# DA1470x register map
Vendor: Dialog; Series: DA1470x; File version: 1.2
CPU: CM33 r0p2, little endian, MPU, FPU, DSP, VTOR, 4 interrupt priority bits
Registers are 32-bit, read-write, reset 0x0 unless marked. A register's access mark holds for its fields unless they carry their own. Offsets are from the block's base; [hi:lo] are bit positions.

## DSI2 — DSI2 registers
Base 0x51001300
0x00 DSI2_CFG_NUM_LANES_REG — configure numer of active lanes
  [3:0] NUM_LANES — Sets the number of active lanes that are to be used for transmitting data. 4'b0000 - No active lanes (reset default) 4'b0001 - 1 Active Lanes 4'b0010 - 2 Active Lanes 4'b0011 - 3 Active Lanes (not supported) 4'b0100 - 4 Active Lanes (not supported)
0x04 DSI2_CFG_CONTINUOUS_HS_CLK_REG
  [0] CONTINUOUS_HS_CLK — Sets the Host Controller into non-continuous MIPI clock mode. When in non-continuous clock mode, the high speed clock will transistion into low power mode between transmissions. 1'b0 - Non-Continuous high speed clock 1'b1 - Continuous high speed clock
0x08 DSI2_CFG_T_PRE_REG
  [7:0] T_PRE — Sets the number of byte clock periods (clk input) that the controller will wait after enabling the clock lane for HS operation before enabling the data lanes for HS operation.
0x0C DSI2_CFG_T_POST_REG
  [7:0] T_POST — Sets the number of byte clock periods (clk input) to wait before putting the clock lane into LP mode after the data lanes have been put into LP mode.
0x10 DSI2_CFG_TX_GAP_REG
  [7:0] TX_GAP — Sets the number of byte clock periods (clk input) that the controller will wait after the clock lane has been put into LP mode before enabling the clock lane for HS mode again.
0x14 DSI2_CFG_AUTOINSERT_EOTP_REG
  [0] AUTOINSERT_EOTP — Enables the Host Controller to automatically insert an EoTp short packet when switching from HS to LP mode. 1b0 eotp is not automatically inserted 1b1 eotp is automatically inserted
0x18 DSI2_CFG_EXT_CMDS_AFT_EOTP_REG
  [7:0] EXTRA_CMDS_AFTER_EOTP — Configures the DSI-2 Host Controller to send extra End Of Transmission Packets after the end of a packet. The value of cfg_extra_cmd_after_eotp is the number of extra EOTP packets sent.
0x1C DSI2_CFG_DISBL_RX_CRC_CHECK_REG
  [0] DISABLE_RX_CRC_CHECK — Prevents the Host from checking the payload CRC in long packets sent from the Peripheral. This input should be set if the peripheral does not support CRC generation.
0x20 DSI2_CFG_HTX_TO_COUNT_REG
  [23:0] HTX_TO_COUNT — Host HS TX Timeout count, HS TX Timeout. Sets the value of the DSI-2 host High Speed TX timeout count in clk clock periods that once reached will initiate a timeout error and follow the recovery procedure documented in the DSI-2 specification. A value of 0x000000 disables the timeout.
0x24 DSI2_CFG_LRX_H_TO_COUNT_REG
  [23:0] LRX_H_TO_COUNT — Host Low Power RX Timeout, LP_RX-H Timeout. Sets the value of the DSI-2 Low Power RX timeout count in clk clock periods that once reached will initiate a timeout error and follow the recovery procedure documented in the DSI-2 specification. A value of 0x000000 disables the timeout.
0x28 DSI2_CFG_BTA_H_TO_COUNT_REG
  [23:0] BTA_H_TO_COUNT — Host Bust Turn Around (BTA) Timout. Sets the value of the DSI-2 Host Bus Turn Around timeout in clk clock periods that once reached will initiate a timeout error. A value of 0x000000 disables the timeout.
0x2C DSI2_CFG_TWAKEUP_REG
  [18:0] TWAKEUP — PHY Twakeup timing parameter. Sets the number of clk_esc clock periods to keep a clock or data lane in Mark-1 state after exiting ULPS. The MIPI PHY spec (D-PHY and C-PHY) requires a minimum of 1ms in Mark-1 state after leaving ULPS. Because each lane requires a wakeup timer, the default hardware configuration ignores the lower 8 bits to reduce logic and area. This gives a timer resolution of 256 esc clocks. If higher resolution is required, the controller can be delivered with full 19 bit support at the expense of extra logic and area.
0x30 DSI2_CFG_DISABLE_BURST_REG
  [0] DISABLE_BURST — Disables packets combined into a burst. Normal DSI-2 operation is to combine packets and send as a burst without returning to LP mode between each packet. 1b0 packets are combined and sent as a burst. (Default DSI-2 behavior) 1b1 Controller returns to LP mode between each packet.
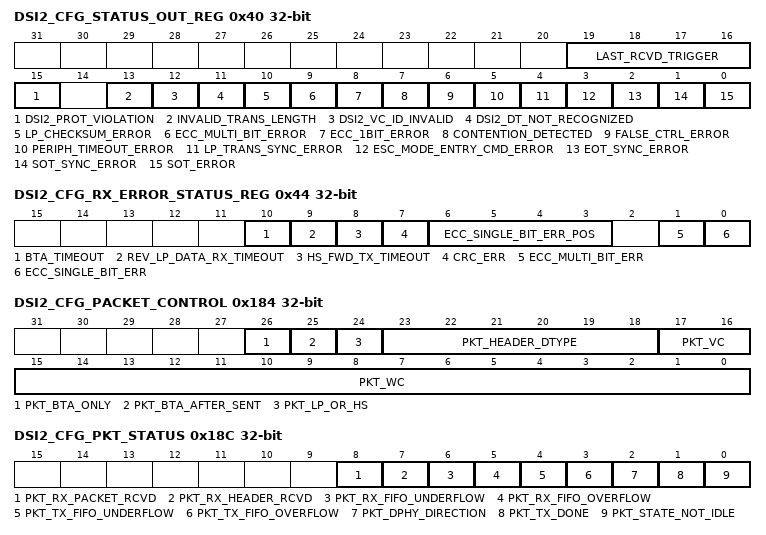
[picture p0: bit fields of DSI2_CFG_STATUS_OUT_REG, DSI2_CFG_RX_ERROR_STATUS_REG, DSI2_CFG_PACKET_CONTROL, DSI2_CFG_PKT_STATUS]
0x40 DSI2_CFG_STATUS_OUT_REG — Contains the status of the status register
  [19:16] LAST_RCVD_TRIGGER ro — Last received Trigger. Current status of the RxTriggerEsc[3:0] from the TX DPHY. Each bit represents one of the possible 4 trigger values was received but unfortunately the MIPI DPHY spec does not define with RxTriggerEsc bit represents which trigger value so the value will be DPHY provider dependent. For Mixel DPHYs the values are as follows: 4b0001 reset trigger ( 01100010 ) 4b0010 unknown trigger 3 ( 01011101 ) 4b0100 unknown trigger 4 ( 00100001 ) 4b1000 unknown trigger 5 ( 10100000 )
  [15] DSI2_PROT_VIOLATION ro — Protocol violation error from peripheral error report, cleared upon read
  [13] INVALID_TRANS_LENGTH ro — Transmission length error from peripheral error report, cleared upon read
  [12] DSI2_VC_ID_INVALID ro — Invalid VC from peripheral error report, cleared upon read
  [11] DSI2_DT_NOT_RECOGNIZED ro — Invalid data type from peripheral error report, cleared upon read
  [10] LP_CHECKSUM_ERROR ro — Checksum error (long packet only) from peripheral error report, cleared upon read
  [9] ECC_MULTI_BIT_ERROR ro — ECC multi-bit error from peripheral error report (not corrected), cleared upon read
  [8] ECC_1BIT_ERROR ro — ECC single bit error from peripheral error report (and corrected), cleared upon read
  [7] CONTENTION_DETECTED ro — Contention Detection from peripheral error report, cleared upon read
  [6] FALSE_CTRL_ERROR ro — False Control Error from peripheral error report, cleared upon read
  [5] PERIPH_TIMEOUT_ERROR ro — Peripheral Timeout error from peripheral error report, cleared upon read
  [4] LP_TRANS_SYNC_ERROR ro — Low Power Transmit Sync error from peripheral error report, cleared upon read
  [3] ESC_MODE_ENTRY_CMD_ERROR ro — Escape Mode Entry Command Error from peripheral error report, cleared upon read
  [2] EOT_SYNC_ERROR ro — End of Transmission Sync Error from peripheral error report, cleared upon read
  [1] SOT_SYNC_ERROR ro — Start of Transmission Sync Error from peripheral error report, cleared upon read
  [0] SOT_ERROR ro — Start of Transmission Error from peripheral error report, cleared upon read
0x44 DSI2_CFG_RX_ERROR_STATUS_REG
  [10] BTA_TIMEOUT ro
  [9] REV_LP_DATA_RX_TIMEOUT ro — Reverse Low Power Data receive timeout
  [8] HS_FWD_TX_TIMEOUT ro — High Speed forward TX timeout
  [7] CRC_ERR ro — CRC error
  [6:3] ECC_SINGLE_BIT_ERR_POS ro — Bit position for ECC single bit error
  [1] ECC_MULTI_BIT_ERR ro — ECC multi bit error
  [0] ECC_SINGLE_BIT_ERR ro — ECC single bit error
0x60 DSI2_CFG_CLK_LANE_EN_REG
  [0] CLK_LANE_EN — Forces PHY Enable n signals to 1'b1 when register is set to 1. See the DSI-2 Controller User Guide description of the input port cfg clk lane en for additional information.
0x64 DSI2_CFG_DATA_LANE_EN_REG
  [1:0] DATA_LANE_EN — Forces PHY Enable n signals to 1'b1 when register is set to 1. See the DSI-2 Controller User Guide description of the input port cfg data lane en for additional informa- tion.
0x100 DSI2_CFG_VID_ENABLE
  [0] VID_ENABLE — Enables the video interface 0 = video interface off; all packets go through rx packet interface 1 = video interface on; video packets routed out video interface
0x104 DSI2_CFG_VID_PIX_P_PACKET
  [15:0] VID_PIX_P_PACKET — Sets the number of pixels that are sent in a packet for each video line. If cfg_vid_packets_per_line is set to 3d1, cfg_vid_pixels_per_packet would be set to the total pixels for each video line. If cfg_vid_packets_per_line is set to 2d2, then this should be set to half the number of pixels on a video line.
0x108 DSI2_CFG_VID_PIX_PAYLOAD_SIZE
  [15:0] VID_PIX_PAYLOAD_SIZE — The number of bytes in a video payload packet. Normally this can be set to zero and let the payload size to be calculated based on cfg_vid_pixels_packet. However, in cases like DSC operation where the number of bytes may not be a multiple of 32 or 64, cfg_vid_pixel_payload_size should be set to reflect the total number of bytes to be sent.
0x10C DSI2_CFG_VID_PIX_ALIGNMENT
  [0] VID_PIX_ALIGNMENT — Some RGB modes can be aligned either MSB or LSB onto the video_pX[35:0] inputs. See section DSI2 spec 4.9.5 for assignments. 0 LSB alignment 1 MSB alignment
0x110 DSI2_CFG_VID_PIX_FORMAT
  [5:0] VID_PIX_FORMAT — Sets the DSI-2 packet type of the pixels. Value is the actual data type sent across the MIPI interface. 0x0B Compressed Pixel Stream, 32-bit or 64-bit 0x0C - Loosely Packed Pixel Stream, 20-bit YCbCr, 4:2:2 0x1C - Packed Pixel Stream, 24-bit YCbCr, 4:2:2 format 0x2C - Packed Pixel Stream, 16-bit YCbCr, 4:2:2 format 0x0D - Packed Pixel Stream, 30-bit RGB, 10-10-10 format 0x1D - Packed Pixel Stream, 36-bit RGB, 12-12-12 format 0x3D - Packed Pixel Stream, 12-bit YCbCr, 4:2:0 format 0x0E - Packed Pixel Stream, 16-bit RGB, 5-6-5 format 0x1E - Packed Pixel Stream, 18-bit RGB, 6-6-6 0x2E - Loosely Packed Pixel Stream, 18-bit RGB, 6-6-6 0x3E - Packed Pixel Stream, 24-bit RGB, 8-8-8
0x114 DSI2_CFG_VID_VSYNC_POLARITY
  [0] VID_VSYNC_POLARITY — Sets polarity of vid_vsync input, 0 active low, 1 active high
0x118 DSI2_CFG_VID_HSYNC_POLARITY
  [0] VID_HSYNC_POLARITY — Sets Polarity of vid_hsync input, 0 active low, 1 active high
0x11C DSI2_CFG_VID_VIDEO_MODE
  [1:0] VID_VID_VIDEO_MODE — Select DSI-2 video mode that the host VID module should generate packets for. 2b00 Non-Burst mode with Sync Pulses 2b01 Non-Burst mode with Sync Events 2b10 Burst Mode 2b11 Reserved, not valid
0x120 DSI2_CFG_VID_OVERRIDE
  [0] VID_OVERRIDE — Overrides internal counters and uses values on configuration inputs. 1b0 Sync timing parameters are calculated off video input. 1b1 Sync timing parameters are set by cfg_vid_* configuration signals.
0x124 DSI2_CFG_VID_START_DELAY
  [15:0] VID_START_DELAY — In order to optimize DSI-2 utility, the video interface buffers a certain number of pixels before initiating a DSI-2 packet. This configuration port controls the number of clk clock cycles to wait before requesting the DSI-2 Host Controller to start sending data.
0x128 DSI2_CFG_VID_HFP
  [15:0] VID_HFP — Sets the DSI-2 packet payload size, in bytes, of the horizontal front porch blanking packet. This input is ignored if cfg_vid_override = 1b0.
0x12C DSI2_CFG_VID_HBP
  [15:0] VID_HBP — Sets the DSI-2 packet payload size, in bytes, of the horizontal back porch blanking packet. This input is ignored if cfg_vid_override = 1b0.
0x130 DSI2_CFG_VID_HSA
  [15:0] VID_HSA — Sets the DSI-2 packet payload size, in bytes, of the horizontal sync width filler blanking packet. This input is ignored if cfg_vid_override = 1b0.
0x134 DSI2_CFG_VID_PACKETS_P_LINE reset 0x1
  [2:0] VID_PACKETS_P_LINE — Sets the number of packets that will be sent for a video line. Default reset value is 3d1. Currently, only the default is supported: 3b001 Video Line is sent in a single packet
0x138 DSI2_CFG_VID_VBP
  [15:0] VID_VBP — Sets the number of lines in the vertical back porch. This input is ignored if cfg_vid_override = 1b0.
0x13C DSI2_CFG_VID_VFP
  [15:0] VID_VFP — Sets the number of lines in the vertical front porch. This input is ignored if cfg_vid_override = 1b0.
0x140 DSI2_CFG_VID_BLLP_MODE
  [0] VID_BLLP_MODE — Optimize bllp periods to Low Power mode when possible 0 blanking packets are sent during BLLP periods 1 LP mode is used for BLLP periods
0x144 DSI2_CFG_VID_USE_NULL_PKT_BLLP
  [0] VID_USE_NULL_PKT_BLLP — Selects type of blanking packet to be sent during bllp region 0 - Blanking packet used in bllp region 1 - Null packet used in bllp region
0x148 DSI2_CFG_VID_VACTIVE
  [15:0] VID_VACTIVE — Sets the number of lines in the vertical active area. This input is ignored if cfg_vid_override = 1b0.
0x14C DSI2_CFG_VID_VC
  [1:0] VID_VC — Sets the Virtual Channel (VC) of packets that will be sent to the receive packet interface. Unless cfg_disable_vc_check is set, packets with VC not equal to this value are discarded and the "DSI-2 VC ID Invalid" bit (bit 12) in the DSI-2 error report is set.
0x180 DSI2_CFG_TX_PAYLOAD (reset mask 0x7FFFFFFF) — TX Payload data write register
  [31:0] CFG_TX_PAYLOAD — Tx Payload data write register. Writes to this registers load the payload fo with 32 bit values.
0x184 DSI2_CFG_PACKET_CONTROL — Tx packet control register
  [26] PKT_BTA_ONLY — Perform BTA only, no packet tx
  [25] PKT_BTA_AFTER_SENT — Perform BTA after packet is sent
  [24] PKT_LP_OR_HS — low power or high speed
  [23:18] PKT_HEADER_DTYPE — Packet header DSI Data Type
  [17:16] PKT_VC — Virtual channel
  [15:0] PKT_WC — Packet word count
0x188 DSI2_CFG_SEND_PACKET — Tx send packet
  [0] CFG_SEND_PACKET — Tx send packet, writing to this register causes the packet described in dsi2 host pkt control to be sent.
0x18C DSI2_CFG_PKT_STATUS — Status of APB to packet interface
  [8] PKT_RX_PACKET_RCVD ro — All RX packet payload data has been received
  [7] PKT_RX_HEADER_RCVD ro — RX packet header has been received
  [6] PKT_RX_FIFO_UNDERFLOW ro — RX fifo underflow
  [5] PKT_RX_FIFO_OVERFLOW ro — RX fifo overflow
  [4] PKT_TX_FIFO_UNDERFLOW ro — TX fifo underflow
  [3] PKT_TX_FIFO_OVERFLOW ro — TX fifo overflow
  [2] PKT_DPHY_DIRECTION ro — DPHY direction 0 - TX had control 1 - RX has control
  [1] PKT_TX_DONE ro — TX packet done
  [0] PKT_STATE_NOT_IDLE ro — State machine not idle
0x190 DSI2_CFG_PKT_WR_LEVEL — Write level of APB to pkt interface fifo
  [15:0] PKT_FIFO_WR_LEVEL ro
0x194 DSI2_CFG_PKT_RD_LEVEL — Read level of APB to pkt interface fifo
  [15:0] PKT_FIFO_RD_LEVEL ro
0x198 DSI2_CFG_PKT_RX_PAYLOAD (reset mask 0x7FFFFFFF) — Packet 2 APB RX payload
  [31:0] PKT_PKT_RX_PAYLOAD ro — APB to pkt interface RX payload read
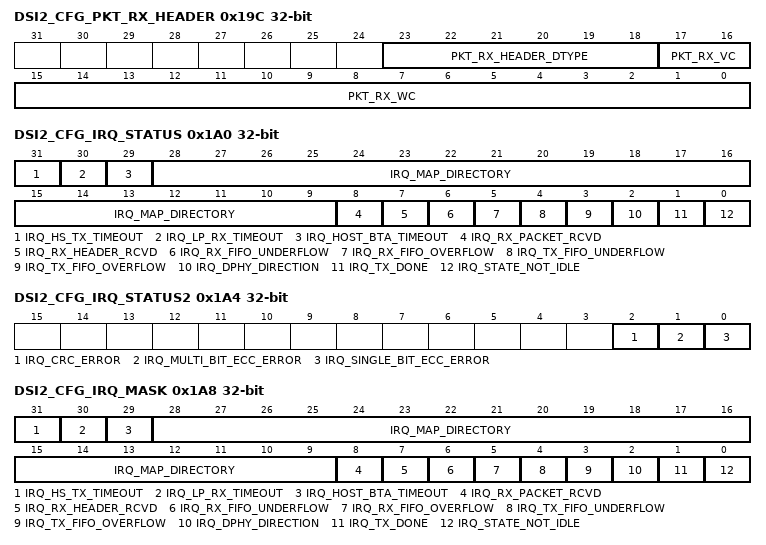
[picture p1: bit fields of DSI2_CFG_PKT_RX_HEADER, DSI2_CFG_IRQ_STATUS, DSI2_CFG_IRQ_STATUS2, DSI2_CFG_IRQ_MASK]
0x19C DSI2_CFG_PKT_RX_HEADER — Packet 2 APB RX header
  [23:18] PKT_RX_HEADER_DTYPE ro — Packet header DSI Data Type
  [17:16] PKT_RX_VC ro — Virtual channel
  [15:0] PKT_RX_WC ro — Packet word count
0x1A0 DSI2_CFG_IRQ_STATUS (reset mask 0x7FFFFFFF) — Status of APB to packet interface, reading will clear IRQ status 1 and 2
  [31] IRQ_HS_TX_TIMEOUT ro — host bta timeout, host controller host bta timeout port
  [30] IRQ_LP_RX_TIMEOUT ro — low power rx timeout, host controller lp rx timeout port
  [29] IRQ_HOST_BTA_TIMEOUT ro — high speed tx timeout, host controller hs tx timeout port
  [28:9] IRQ_MAP_DIRECTORY ro — map directory to dsi host controller status out port bit descriptions
  [8] IRQ_RX_PACKET_RCVD ro — All RX packet payload data has been received
  [7] IRQ_RX_HEADER_RCVD ro — RX packet header has been received
  [6] IRQ_RX_FIFO_UNDERFLOW ro — RX fifo underflow
  [5] IRQ_RX_FIFO_OVERFLOW ro — RX fifo overflow
  [4] IRQ_TX_FIFO_UNDERFLOW ro — TX fifo underflow
  [3] IRQ_TX_FIFO_OVERFLOW ro — TX fifo overflow
  [2] IRQ_DPHY_DIRECTION ro — DPHY direction 0 - TX had control 1 - RX has control
  [1] IRQ_TX_DONE ro — TX packet done
  [0] IRQ_STATE_NOT_IDLE ro — State machine not idle
0x1A4 DSI2_CFG_IRQ_STATUS2 — Status of APB to packet interface part 2, read part 2 first then dsi2 host irq 2
  [2] IRQ_CRC_ERROR ro — CRC error
  [1] IRQ_MULTI_BIT_ECC_ERROR ro — TX packet done
  [0] IRQ_SINGLE_BIT_ECC_ERROR ro — Single bit ecc error
0x1A8 DSI2_CFG_IRQ_MASK (reset mask 0x7FFFFFFF) — Status of APB to packet interface, reading will clear IRQ status 1 and 2
  [31] IRQ_HS_TX_TIMEOUT — host bta timeout, host controller host bta timeout port
  [30] IRQ_LP_RX_TIMEOUT — low power rx timeout, host controller lp rx timeout port
  [29] IRQ_HOST_BTA_TIMEOUT — high speed tx timeout, host controller hs tx timeout port
  [28:9] IRQ_MAP_DIRECTORY — map directory to dsi host controller status out port bit descriptions
  [8] IRQ_RX_PACKET_RCVD — All RX packet payload data has been received
  [7] IRQ_RX_HEADER_RCVD — RX packet header has been received
  [6] IRQ_RX_FIFO_UNDERFLOW — RX fifo underflow
  [5] IRQ_RX_FIFO_OVERFLOW — RX fifo overflow
  [4] IRQ_TX_FIFO_UNDERFLOW — TX fifo underflow
  [3] IRQ_TX_FIFO_OVERFLOW — TX fifo overflow
  [2] IRQ_DPHY_DIRECTION — DPHY direction 0 - TX had control 1 - RX has control
  [1] IRQ_TX_DONE — TX packet done
  [0] IRQ_STATE_NOT_IDLE — State machine not idle
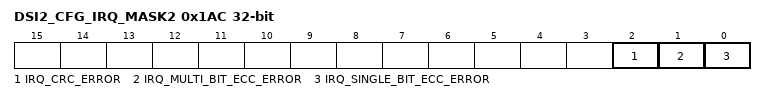
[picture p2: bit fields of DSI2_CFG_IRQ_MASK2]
0x1AC DSI2_CFG_IRQ_MASK2 — Status of APB to packet interface part 2, read part 2 first then dsi2 host irq 2
  [2] IRQ_CRC_ERROR — CRC error
  [1] IRQ_MULTI_BIT_ECC_ERROR — TX packet done
  [0] IRQ_SINGLE_BIT_ECC_ERROR — Single bit ecc error
